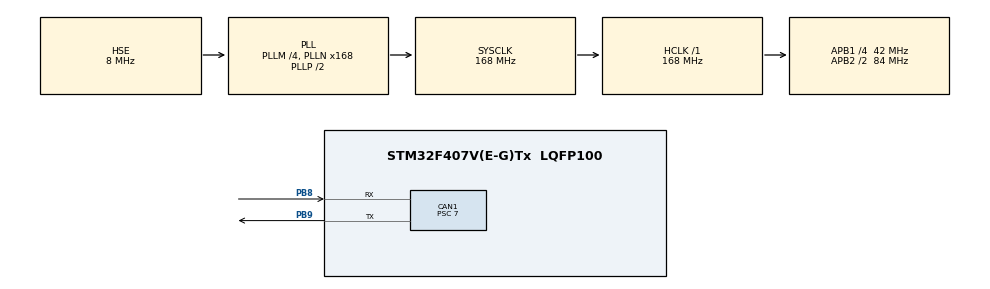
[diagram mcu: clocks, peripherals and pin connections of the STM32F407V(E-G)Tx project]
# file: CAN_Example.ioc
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CAN1.BS1=CAN_BS1_10TQ
CAN1.CalculateTimeQuantum=166.66666666666669
CAN1.Prescaler=7
Mcu.Family=STM32F4
Mcu.Name=STM32F407V(E-G)Tx
Mcu.Package=LQFP100
NVIC.CAN1_RX0_IRQn=true\:0\:2\:false\:false\:true\:true\:true
NVIC.PriorityGroup=NVIC_PRIORITYGROUP_0
PB8.Mode=Master
PB8.Signal=CAN1_RX
PB9.Mode=Master
PB9.Signal=CAN1_TX
PH0-OSC_IN.Mode=HSE-External-Oscillator
PH0-OSC_IN.Signal=RCC_OSC_IN
PH1-OSC_OUT.Mode=HSE-External-Oscillator
PH1-OSC_OUT.Signal=RCC_OSC_OUT
ProjectManager.HeapSize=0x200
ProjectManager.StackSize=0x400
ProjectManager.TargetToolchain=STM32CubeIDE
RCC.48MHZClocksFreq_Value=48000000
RCC.AHBFreq_Value=168000000
RCC.APB1CLKDivider=RCC_HCLK_DIV4
RCC.APB1Freq_Value=42000000
RCC.APB1TimFreq_Value=84000000
RCC.APB2CLKDivider=RCC_HCLK_DIV2
RCC.APB2Freq_Value=84000000
RCC.APB2TimFreq_Value=168000000
RCC.CortexFreq_Value=168000000
RCC.HCLKFreq_Value=168000000
RCC.HSE_VALUE=8000000
RCC.HSI_VALUE=16000000
RCC.LSE_VALUE=32768
RCC.PLLM=4
RCC.PLLN=168
RCC.PLLQ=7
RCC.PLLSourceVirtual=RCC_PLLSOURCE_HSE
RCC.SYSCLKFreq_VALUE=168000000
RCC.SYSCLKSource=RCC_SYSCLKSOURCE_PLLCLK
RCC.VCOOutputFreq_Value=336000000
board=STM32F407G-DISC1

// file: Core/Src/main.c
/* USER CODE BEGIN Header */
/**
  ******************************************************************************
  * @file           : main.c
  * @brief          : Main program body
  ******************************************************************************
  * @attention
  *
  * <h2><center>&copy; Copyright (c) 2021 STMicroelectronics.
  * All rights reserved.</center></h2>
  *
  * This software component is licensed by ST under BSD 3-Clause license,
  * the "License"; You may not use this file except in compliance with the
  * License. You may obtain a copy of the License at:
  *                        opensource.org/licenses/BSD-3-Clause
  *
  ******************************************************************************
  */
/* USER CODE END Header */
#include "main.h"

CAN_HandleTypeDef hcan1;

/* USER CODE BEGIN PV */
CAN_TxHeaderTypeDef Header;
uint32_t TxMailbox;
CAN_FilterTypeDef sFilterConfig;
/* USER CODE END PV */

void SystemClock_Config(void);
static void MX_GPIO_Init(void);
static void MX_CAN1_Init(void);

int main(void)
{

  /* MCU Configuration--------------------------------------------------------*/

  /* Reset of all peripherals, Initializes the Flash interface and the Systick. */
  HAL_Init();

  /* Configure the system clock */
  SystemClock_Config();

  /* Initialize all configured peripherals */
  MX_GPIO_Init();
  MX_CAN1_Init();
  /* USER CODE BEGIN 2 */
  HAL_Delay(100);
  uint8_t canDataBuffer[8] = {0};
  canDataBuffer[0] = 0x31;
  canDataBuffer[1] = 0x01;
  canDataBuffer[2] = 0x80;
  canDataBuffer[3] = 0x87;

  Header.StdId = 0x244;
  Header.DLC = 4;
  Header.IDE = CAN_ID_STD;
  Header.RTR = CAN_RTR_DATA;

  sFilterConfig.FilterFIFOAssignment = CAN_FILTER_FIFO0;
  sFilterConfig.FilterIdHigh = 0x245 << 5;
  sFilterConfig.FilterIdLow = 0;
  sFilterConfig.FilterMaskIdHigh = 0;
  sFilterConfig.FilterMaskIdLow = 0;
  sFilterConfig.FilterScale = CAN_FILTERSCALE_32BIT;
  sFilterConfig.FilterActivation = ENABLE;

  HAL_CAN_ConfigFilter(&hcan1, &sFilterConfig);
  HAL_CAN_Start(&hcan1);
  HAL_CAN_ActivateNotification(&hcan1, CAN_IT_RX_FIFO0_MSG_PENDING);
  /* USER CODE END 2 */

  /* Infinite loop */
  /* USER CODE BEGIN WHILE */
  while (1)
  {
	  HAL_CAN_AddTxMessage(&hcan1, &Header, canDataBuffer, &TxMailbox);
	  HAL_Delay(500);
    /* USER CODE END WHILE */

  }
}

void SystemClock_Config(void)
{
  RCC_OscInitTypeDef RCC_OscInitStruct = {0};
  RCC_ClkInitTypeDef RCC_ClkInitStruct = {0};

  /** Configure the main internal regulator output voltage
  */
  __HAL_RCC_PWR_CLK_ENABLE();
  __HAL_PWR_VOLTAGESCALING_CONFIG(PWR_REGULATOR_VOLTAGE_SCALE1);
  /** Initializes the RCC Oscillators according to the specified parameters
  * in the RCC_OscInitTypeDef structure.
  */
  RCC_OscInitStruct.OscillatorType = RCC_OSCILLATORTYPE_HSE;
  RCC_OscInitStruct.HSEState = RCC_HSE_ON;
  RCC_OscInitStruct.PLL.PLLState = RCC_PLL_ON;
  RCC_OscInitStruct.PLL.PLLSource = RCC_PLLSOURCE_HSE;
  RCC_OscInitStruct.PLL.PLLM = 4;
  RCC_OscInitStruct.PLL.PLLN = 168;
  RCC_OscInitStruct.PLL.PLLP = RCC_PLLP_DIV2;
  RCC_OscInitStruct.PLL.PLLQ = 7;
  if (HAL_RCC_OscConfig(&RCC_OscInitStruct) != HAL_OK)
  {
    Error_Handler();
  }
  /** Initializes the CPU, AHB and APB buses clocks
  */
  RCC_ClkInitStruct.ClockType = RCC_CLOCKTYPE_HCLK|RCC_CLOCKTYPE_SYSCLK
                              |RCC_CLOCKTYPE_PCLK1|RCC_CLOCKTYPE_PCLK2;
  RCC_ClkInitStruct.SYSCLKSource = RCC_SYSCLKSOURCE_PLLCLK;
  RCC_ClkInitStruct.AHBCLKDivider = RCC_SYSCLK_DIV1;
  RCC_ClkInitStruct.APB1CLKDivider = RCC_HCLK_DIV4;
  RCC_ClkInitStruct.APB2CLKDivider = RCC_HCLK_DIV2;

  if (HAL_RCC_ClockConfig(&RCC_ClkInitStruct, FLASH_LATENCY_5) != HAL_OK)
  {
    Error_Handler();
  }
}

static void MX_CAN1_Init(void)
{

  hcan1.Instance = CAN1;
  hcan1.Init.Prescaler = 7;
  hcan1.Init.Mode = CAN_MODE_NORMAL;
  hcan1.Init.SyncJumpWidth = CAN_SJW_1TQ;
  hcan1.Init.TimeSeg1 = CAN_BS1_10TQ;
  hcan1.Init.TimeSeg2 = CAN_BS2_1TQ;
  hcan1.Init.TimeTriggeredMode = DISABLE;
  hcan1.Init.AutoBusOff = DISABLE;
  hcan1.Init.AutoWakeUp = DISABLE;
  hcan1.Init.AutoRetransmission = DISABLE;
  hcan1.Init.ReceiveFifoLocked = DISABLE;
  hcan1.Init.TransmitFifoPriority = DISABLE;
  if (HAL_CAN_Init(&hcan1) != HAL_OK)
  {
    Error_Handler();
  }

}

static void MX_GPIO_Init(void)
{

  /* GPIO Ports Clock Enable */
  __HAL_RCC_GPIOH_CLK_ENABLE();
  __HAL_RCC_GPIOB_CLK_ENABLE();

}

void Error_Handler(void)
{
}

/************************ (C) COPYRIGHT STMicroelectronics *****END OF FILE****/
